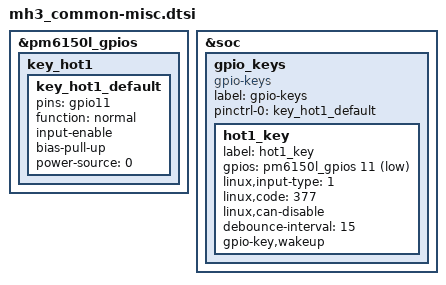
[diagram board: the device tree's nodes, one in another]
&pm6150l_gpios {
	key_hot1 {
		key_hot1_default: key_hot1_default {
			pins = "gpio11";
			function = "normal";
			input-enable;
			bias-pull-up;
			power-source = <0>;
		};
	};
};

&soc {
	gpio_keys {
		compatible = "gpio-keys";
		label = "gpio-keys";

		pinctrl-names = "default";
		pinctrl-0 = <&key_hot1_default>;

		hot1_key {
			label = "hot1_key";
			gpios = <&pm6150l_gpios 11 GPIO_ACTIVE_LOW>;
			linux,input-type = <1>;
			linux,code = <377>;
			linux,can-disable;
			debounce-interval = <15>;
			gpio-key,wakeup;
		};
	};
};
